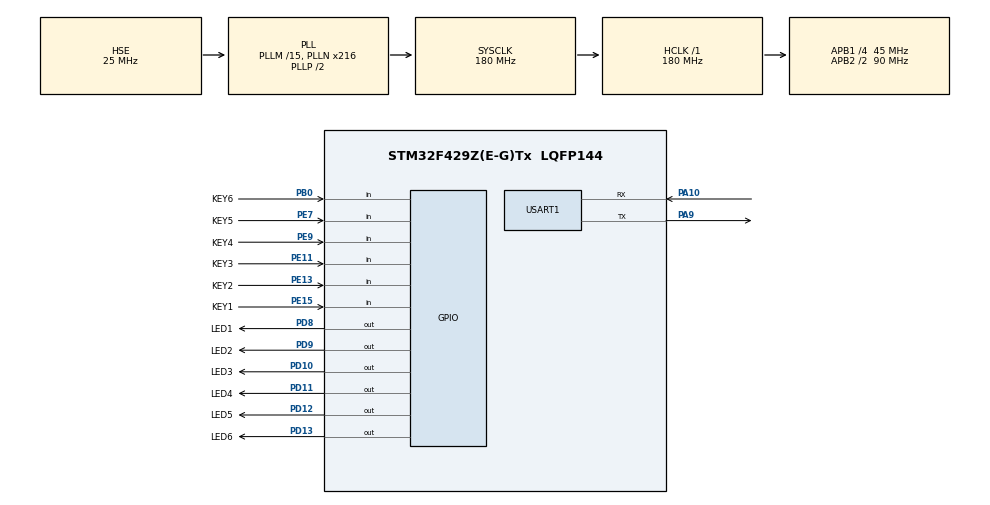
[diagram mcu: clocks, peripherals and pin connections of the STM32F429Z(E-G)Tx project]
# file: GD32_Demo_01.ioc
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Dma.Request0=USART1_RX
Dma.USART1_RX.0.Direction=DMA_PERIPH_TO_MEMORY
Dma.USART1_RX.0.FIFOMode=DMA_FIFOMODE_DISABLE
Dma.USART1_RX.0.Instance=DMA2_Stream2
Dma.USART1_RX.0.MemDataAlignment=DMA_MDATAALIGN_BYTE
Dma.USART1_RX.0.MemInc=DMA_MINC_ENABLE
Dma.USART1_RX.0.Mode=DMA_CIRCULAR
Dma.USART1_RX.0.PeriphDataAlignment=DMA_PDATAALIGN_BYTE
Dma.USART1_RX.0.PeriphInc=DMA_PINC_DISABLE
Dma.USART1_RX.0.Priority=DMA_PRIORITY_LOW
Mcu.Family=STM32F4
Mcu.Name=STM32F429Z(E-G)Tx
Mcu.Package=LQFP144
NVIC.DMA2_Stream2_IRQn=true\:0\:0\:false\:false\:true\:false\:true\:true
NVIC.PriorityGroup=NVIC_PRIORITYGROUP_4
NVIC.USART1_IRQn=true\:0\:0\:false\:false\:true\:true\:true\:true
PA10.Mode=Asynchronous
PA10.Signal=USART1_RX
PA13.Mode=Serial_Wire
PA13.Signal=SYS_JTMS-SWDIO
PA14.Mode=Serial_Wire
PA14.Signal=SYS_JTCK-SWCLK
PA9.Mode=Asynchronous
PA9.Signal=USART1_TX
PB0.GPIO_Label=KEY6
PB0.GPIO_PuPd=GPIO_PULLUP
PB0.Signal=GPIO_Input
PC14/OSC32_IN.Mode=LSE-External-Oscillator
PC14/OSC32_IN.Signal=RCC_OSC32_IN
PC15/OSC32_OUT.Mode=LSE-External-Oscillator
PC15/OSC32_OUT.Signal=RCC_OSC32_OUT
PD10.GPIO_Label=LED3
PD10.Signal=GPIO_Output
PD11.GPIO_Label=LED4
PD11.Signal=GPIO_Output
PD12.GPIO_Label=LED5
PD12.Signal=GPIO_Output
PD13.GPIO_Label=LED6
PD13.Signal=GPIO_Output
PD8.GPIO_Label=LED1
PD8.Signal=GPIO_Output
PD9.GPIO_Label=LED2
PD9.Signal=GPIO_Output
PE11.GPIO_Label=KEY3
PE11.GPIO_PuPd=GPIO_PULLUP
PE11.Signal=GPIO_Input
PE13.GPIO_Label=KEY2
PE13.GPIO_PuPd=GPIO_PULLUP
PE13.Signal=GPIO_Input
PE15.GPIO_Label=KEY1
PE15.GPIO_PuPd=GPIO_PULLUP
PE15.Signal=GPIO_Input
PE7.GPIO_Label=KEY5
PE7.GPIO_PuPd=GPIO_PULLUP
PE7.Signal=GPIO_Input
PE9.GPIO_Label=KEY4
PE9.GPIO_PuPd=GPIO_PULLUP
PE9.Signal=GPIO_Input
PH0/OSC_IN.Mode=HSE-External-Oscillator
PH0/OSC_IN.Signal=RCC_OSC_IN
PH1/OSC_OUT.Mode=HSE-External-Oscillator
PH1/OSC_OUT.Signal=RCC_OSC_OUT
ProjectManager.HeapSize=0x400
ProjectManager.StackSize=0x800
ProjectManager.TargetToolchain=MDK-ARM V5.32
RCC.48MHZClocksFreq_Value=90000000
RCC.AHBFreq_Value=180000000
RCC.APB1CLKDivider=RCC_HCLK_DIV4
RCC.APB1Freq_Value=45000000
RCC.APB1TimFreq_Value=90000000
RCC.APB2CLKDivider=RCC_HCLK_DIV2
RCC.APB2Freq_Value=90000000
RCC.APB2TimFreq_Value=180000000
RCC.CortexFreq_Value=180000000
RCC.HCLKFreq_Value=180000000
RCC.HSE_VALUE=25000000
RCC.HSI_VALUE=16000000
RCC.PLLM=15
RCC.PLLN=216
RCC.PLLSourceVirtual=RCC_PLLSOURCE_HSE
RCC.SYSCLKFreq_VALUE=180000000
RCC.SYSCLKSource=RCC_SYSCLKSOURCE_PLLCLK
RCC.VCOOutputFreq_Value=360000000
USART1.VirtualMode=VM_ASYNC
board=custom

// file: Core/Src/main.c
/* USER CODE BEGIN Header */
/**
  ******************************************************************************
  * @file           : main.c
  * @brief          : Main program body
  ******************************************************************************
  * @attention
  *
  * Copyright (c) 2025 STMicroelectronics.
  * All rights reserved.
  *
  * This software is licensed under terms that can be found in the LICENSE file
  * in the root directory of this software component.
  * If no LICENSE file comes with this software, it is provided AS-IS.
  *
  ******************************************************************************
  */
/* USER CODE END Header */
#include "main.h"
#include "dma.h"
#include "usart.h"
#include "gpio.h"

/* USER CODE BEGIN Includes */
#include "scheduler.h"
/* USER CODE END Includes */

void SystemClock_Config(void);

int main(void)
{

  /* MCU Configuration--------------------------------------------------------*/

  /* Reset of all peripherals, Initializes the Flash interface and the Systick. */
  HAL_Init();

  /* Configure the system clock */
  SystemClock_Config();

  /* Initialize all configured peripherals */
  MX_GPIO_Init();
  MX_DMA_Init();
  MX_USART1_UART_Init();
  /* USER CODE BEGIN 2 */
	HAL_UARTEx_ReceiveToIdle_DMA(&huart1, uart_rx_dma_buffer, sizeof(uart_rx_dma_buffer));//DMA也要首次 启动接收
	__HAL_DMA_DISABLE_IT(&hdma_usart1_rx, DMA_IT_HT);//关闭半满中断
	rt_ringbuffer_init(&uart_ringbuffer,ringbuffer_pool,sizeof(ringbuffer_pool));//初始化ringbuffer 也就是让实例化的uart_ringbuffer结构体绑定为其分配的缓存区域ringbuffer_pool

	my_ebtn_init();
	scheduler_init();
  /* USER CODE END 2 */

  /* Infinite loop */
  while (1)
  {

    /* USER CODE BEGIN 3 */
		scheduler_run();

  }
  /* USER CODE END 3 */
}

void SystemClock_Config(void)
{
  RCC_OscInitTypeDef RCC_OscInitStruct = {0};
  RCC_ClkInitTypeDef RCC_ClkInitStruct = {0};

  /** Configure the main internal regulator output voltage
  */
  __HAL_RCC_PWR_CLK_ENABLE();
  __HAL_PWR_VOLTAGESCALING_CONFIG(PWR_REGULATOR_VOLTAGE_SCALE1);

  /** Initializes the RCC Oscillators according to the specified parameters
  * in the RCC_OscInitTypeDef structure.
  */
  RCC_OscInitStruct.OscillatorType = RCC_OSCILLATORTYPE_HSE;
  RCC_OscInitStruct.HSEState = RCC_HSE_ON;
  RCC_OscInitStruct.PLL.PLLState = RCC_PLL_ON;
  RCC_OscInitStruct.PLL.PLLSource = RCC_PLLSOURCE_HSE;
  RCC_OscInitStruct.PLL.PLLM = 15;
  RCC_OscInitStruct.PLL.PLLN = 216;
  RCC_OscInitStruct.PLL.PLLP = RCC_PLLP_DIV2;
  RCC_OscInitStruct.PLL.PLLQ = 4;
  if (HAL_RCC_OscConfig(&RCC_OscInitStruct) != HAL_OK)
  {
    Error_Handler();
  }

  /** Activate the Over-Drive mode
  */
  if (HAL_PWREx_EnableOverDrive() != HAL_OK)
  {
    Error_Handler();
  }

  /** Initializes the CPU, AHB and APB buses clocks
  */
  RCC_ClkInitStruct.ClockType = RCC_CLOCKTYPE_HCLK|RCC_CLOCKTYPE_SYSCLK
                              |RCC_CLOCKTYPE_PCLK1|RCC_CLOCKTYPE_PCLK2;
  RCC_ClkInitStruct.SYSCLKSource = RCC_SYSCLKSOURCE_PLLCLK;
  RCC_ClkInitStruct.AHBCLKDivider = RCC_SYSCLK_DIV1;
  RCC_ClkInitStruct.APB1CLKDivider = RCC_HCLK_DIV4;
  RCC_ClkInitStruct.APB2CLKDivider = RCC_HCLK_DIV2;

  if (HAL_RCC_ClockConfig(&RCC_ClkInitStruct, FLASH_LATENCY_5) != HAL_OK)
  {
    Error_Handler();
  }
}

void Error_Handler(void)
{
  __disable_irq();
  while (1)
  {
  }
}
